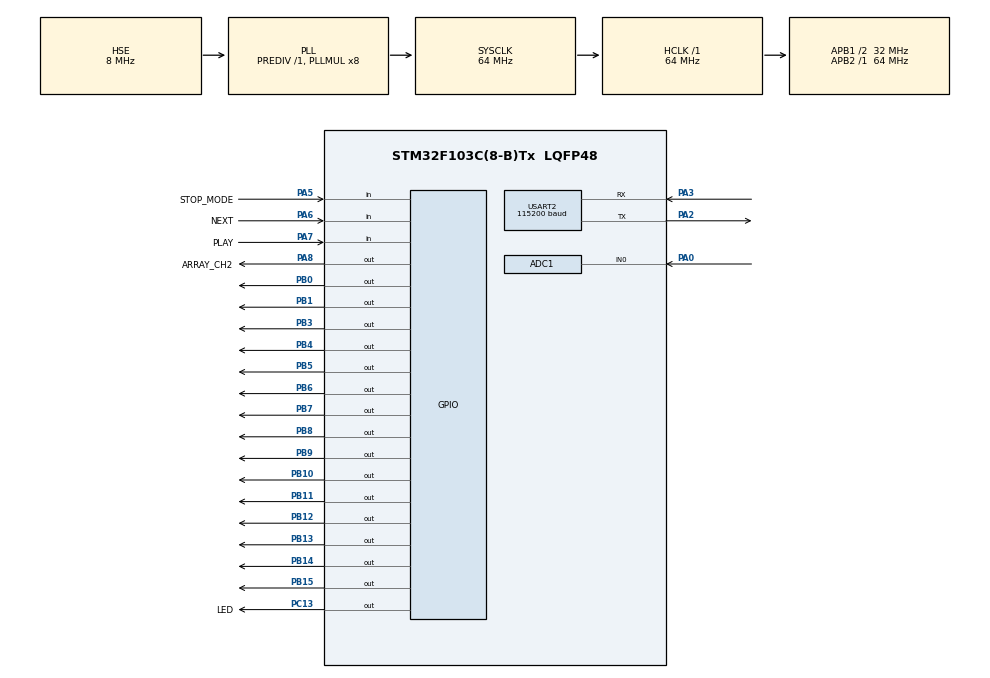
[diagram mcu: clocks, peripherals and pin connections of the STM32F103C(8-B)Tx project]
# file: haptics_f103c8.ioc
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ADC1.Channel-0\#ChannelRegularConversion=ADC_CHANNEL_0
ADC1.ExternalTrigConv=ADC_EXTERNALTRIGCONV_T3_TRGO
ADC1.NbrOfConversionFlag=1
ADC1.Rank-0\#ChannelRegularConversion=1
ADC1.SamplingTime-0\#ChannelRegularConversion=ADC_SAMPLETIME_7CYCLES_5
ADC1.master=1
Dma.ADC1.0.Direction=DMA_PERIPH_TO_MEMORY
Dma.ADC1.0.Instance=DMA1_Channel1
Dma.ADC1.0.MemDataAlignment=DMA_MDATAALIGN_HALFWORD
Dma.ADC1.0.MemInc=DMA_MINC_ENABLE
Dma.ADC1.0.Mode=DMA_NORMAL
Dma.ADC1.0.PeriphDataAlignment=DMA_PDATAALIGN_HALFWORD
Dma.ADC1.0.PeriphInc=DMA_PINC_DISABLE
Dma.ADC1.0.Priority=DMA_PRIORITY_LOW
Dma.Request0=ADC1
Dma.Request1=TIM1_UP
Dma.Request2=TIM1_CH1
Dma.TIM1_CH1.2.Direction=DMA_MEMORY_TO_PERIPH
Dma.TIM1_CH1.2.Instance=DMA1_Channel2
Dma.TIM1_CH1.2.MemDataAlignment=DMA_MDATAALIGN_HALFWORD
Dma.TIM1_CH1.2.MemInc=DMA_MINC_ENABLE
Dma.TIM1_CH1.2.Mode=DMA_CIRCULAR
Dma.TIM1_CH1.2.PeriphDataAlignment=DMA_PDATAALIGN_HALFWORD
Dma.TIM1_CH1.2.PeriphInc=DMA_PINC_DISABLE
Dma.TIM1_CH1.2.Priority=DMA_PRIORITY_VERY_HIGH
Dma.TIM1_UP.1.Direction=DMA_MEMORY_TO_PERIPH
Dma.TIM1_UP.1.Instance=DMA1_Channel5
Dma.TIM1_UP.1.MemDataAlignment=DMA_MDATAALIGN_HALFWORD
Dma.TIM1_UP.1.MemInc=DMA_MINC_ENABLE
Dma.TIM1_UP.1.Mode=DMA_CIRCULAR
Dma.TIM1_UP.1.PeriphDataAlignment=DMA_PDATAALIGN_HALFWORD
Dma.TIM1_UP.1.PeriphInc=DMA_PINC_DISABLE
Dma.TIM1_UP.1.Priority=DMA_PRIORITY_VERY_HIGH
Mcu.Family=STM32F1
Mcu.Name=STM32F103C(8-B)Tx
Mcu.Package=LQFP48
NVIC.DMA1_Channel1_IRQn=true\:2\:0\:false\:false\:true\:false\:true\:true
NVIC.DMA1_Channel2_IRQn=true\:1\:0\:false\:false\:true\:false\:true\:true
NVIC.DMA1_Channel5_IRQn=true\:1\:0\:false\:false\:true\:false\:true\:true
NVIC.PriorityGroup=NVIC_PRIORITYGROUP_4
NVIC.USART2_IRQn=true\:0\:0\:false\:false\:true\:false\:true\:true
PA0-WKUP.Signal=ADCx_IN0
PA13.Mode=Serial_Wire
PA13.Signal=SYS_JTMS-SWDIO
PA14.Mode=Serial_Wire
PA14.Signal=SYS_JTCK-SWCLK
PA2.Mode=Asynchronous
PA2.Signal=USART2_TX
PA3.GPIO_PuPd=GPIO_PULLUP
PA3.Mode=Asynchronous
PA3.Signal=USART2_RX
PA5.GPIO_Label=STOP_MODE
PA5.GPIO_PuPd=GPIO_PULLUP
PA5.Signal=GPIO_Input
PA6.GPIO_Label=NEXT
PA6.GPIO_PuPd=GPIO_PULLUP
PA6.Signal=GPIO_Input
PA7.GPIO_Label=PLAY
PA7.GPIO_PuPd=GPIO_PULLUP
PA7.Signal=GPIO_Input
PA8.GPIO_Label=ARRAY_CH2
PA8.GPIO_Speed=GPIO_SPEED_FREQ_HIGH
PA8.Signal=GPIO_Output
PB0.GPIO_Speed=GPIO_SPEED_FREQ_HIGH
PB0.Signal=GPIO_Output
PB1.GPIO_Speed=GPIO_SPEED_FREQ_HIGH
PB1.Signal=GPIO_Output
PB10.GPIO_Speed=GPIO_SPEED_FREQ_HIGH
PB10.Signal=GPIO_Output
PB11.GPIO_Speed=GPIO_SPEED_FREQ_HIGH
PB11.Signal=GPIO_Output
PB12.GPIO_Speed=GPIO_SPEED_FREQ_HIGH
PB12.Signal=GPIO_Output
PB13.GPIO_Speed=GPIO_SPEED_FREQ_HIGH
PB13.Signal=GPIO_Output
PB14.GPIO_Speed=GPIO_SPEED_FREQ_HIGH
PB14.Signal=GPIO_Output
PB15.GPIO_Speed=GPIO_SPEED_FREQ_HIGH
PB15.Signal=GPIO_Output
PB3.GPIO_Speed=GPIO_SPEED_FREQ_HIGH
PB3.Signal=GPIO_Output
PB4.GPIO_Speed=GPIO_SPEED_FREQ_HIGH
PB4.Signal=GPIO_Output
PB5.GPIO_Speed=GPIO_SPEED_FREQ_HIGH
PB5.Signal=GPIO_Output
PB6.GPIO_Speed=GPIO_SPEED_FREQ_HIGH
PB6.Signal=GPIO_Output
PB7.GPIO_Speed=GPIO_SPEED_FREQ_HIGH
PB7.Signal=GPIO_Output
PB8.GPIO_Speed=GPIO_SPEED_FREQ_HIGH
PB8.Signal=GPIO_Output
PB9.GPIO_Speed=GPIO_SPEED_FREQ_HIGH
PB9.Signal=GPIO_Output
PC13-TAMPER-RTC.GPIO_Label=LED
PC13-TAMPER-RTC.PinState=GPIO_PIN_SET
PC13-TAMPER-RTC.Signal=GPIO_Output
PD0-OSC_IN.Mode=HSE-External-Oscillator
PD0-OSC_IN.Signal=RCC_OSC_IN
PD1-OSC_OUT.Mode=HSE-External-Oscillator
PD1-OSC_OUT.Signal=RCC_OSC_OUT
ProjectManager.HeapSize=0x0
ProjectManager.StackSize=0x800
ProjectManager.TargetToolchain=STM32CubeIDE
RCC.ADCPresc=RCC_ADCPCLK2_DIV6
RCC.AHBFreq_Value=64000000
RCC.APB1CLKDivider=RCC_HCLK_DIV2
RCC.APB1Freq_Value=32000000
RCC.APB1TimFreq_Value=64000000
RCC.APB2Freq_Value=64000000
RCC.APB2TimFreq_Value=64000000
RCC.HCLKFreq_Value=64000000
RCC.HSE_VALUE=8000000
RCC.PLLMUL=RCC_PLL_MUL8
RCC.PLLSourceVirtual=RCC_PLLSOURCE_HSE
RCC.SYSCLKFreq_VALUE=64000000
RCC.SYSCLKSource=RCC_SYSCLKSOURCE_PLLCLK
RCC.USBFreq_Value=64000000
SH.ADCx_IN0.0=ADC1_IN0,IN0
TIM1.Channel-Output Compare1 No Output=TIM_CHANNEL_1
TIM1.Period=24
TIM1.Prescaler=0
TIM1.Pulse=1
TIM3.Period=159
TIM3.Prescaler=0
TIM3.TIM_MasterOutputTrigger=TIM_TRGO_UPDATE
USART2.BaudRate=115200
USART2.VirtualMode=VM_ASYNC
VP_TIM1_VS_ClockSourceINT.Mode=Internal
VP_TIM1_VS_no_output1.Mode=Output Compare1 No Output
VP_TIM3_VS_ClockSourceINT.Mode=Internal
board=custom

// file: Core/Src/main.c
/* USER CODE BEGIN Header */
/**
  ******************************************************************************
  * @file           : main.c
  * @brief          : Main program body
  ******************************************************************************
  * @attention
  *
  * Copyright (c) 2026 STMicroelectronics.
  * All rights reserved.
  *
  * This software is licensed under terms that can be found in the LICENSE file
  * in the root directory of this software component.
  * If no LICENSE file comes with this software, it is provided AS-IS.
  *
  ******************************************************************************
  */
/* USER CODE END Header */
#include "main.h"
#include "adc.h"
#include "dma.h"
#include "tim.h"
#include "usart.h"
#include "gpio.h"

/* USER CODE BEGIN Includes */
#include "app_f103.h"
/* USER CODE END Includes */

void SystemClock_Config(void);

int main(void)
{

  /* MCU Configuration--------------------------------------------------------*/

  /* Reset of all peripherals, Initializes the Flash interface and the Systick. */
  HAL_Init();

  /* Configure the system clock */
  SystemClock_Config();

  /* Initialize all configured peripherals */
  MX_GPIO_Init();
  MX_DMA_Init();
  MX_TIM1_Init();
  MX_TIM3_Init();
  MX_ADC1_Init();
  MX_USART2_UART_Init();
  /* USER CODE BEGIN 2 */
  app_f103_init();
  /* USER CODE END 2 */

  /* Infinite loop */
  while (1)
  {

    /* USER CODE BEGIN 3 */
    app_f103_poll();
  }
  /* USER CODE END 3 */
}

void SystemClock_Config(void)
{
  RCC_OscInitTypeDef RCC_OscInitStruct = {0};
  RCC_ClkInitTypeDef RCC_ClkInitStruct = {0};
  RCC_PeriphCLKInitTypeDef PeriphClkInit = {0};

  /** Initializes the RCC Oscillators according to the specified parameters
  * in the RCC_OscInitTypeDef structure.
  */
  RCC_OscInitStruct.OscillatorType = RCC_OSCILLATORTYPE_HSE;
  RCC_OscInitStruct.HSEState = RCC_HSE_ON;
  RCC_OscInitStruct.HSEPredivValue = RCC_HSE_PREDIV_DIV1;
  RCC_OscInitStruct.HSIState = RCC_HSI_ON;
  RCC_OscInitStruct.PLL.PLLState = RCC_PLL_ON;
  RCC_OscInitStruct.PLL.PLLSource = RCC_PLLSOURCE_HSE;
  RCC_OscInitStruct.PLL.PLLMUL = RCC_PLL_MUL8;
  if (HAL_RCC_OscConfig(&RCC_OscInitStruct) != HAL_OK)
  {
    Error_Handler();
  }

  /** Initializes the CPU, AHB and APB buses clocks
  */
  RCC_ClkInitStruct.ClockType = RCC_CLOCKTYPE_HCLK|RCC_CLOCKTYPE_SYSCLK
                              |RCC_CLOCKTYPE_PCLK1|RCC_CLOCKTYPE_PCLK2;
  RCC_ClkInitStruct.SYSCLKSource = RCC_SYSCLKSOURCE_PLLCLK;
  RCC_ClkInitStruct.AHBCLKDivider = RCC_SYSCLK_DIV1;
  RCC_ClkInitStruct.APB1CLKDivider = RCC_HCLK_DIV2;
  RCC_ClkInitStruct.APB2CLKDivider = RCC_HCLK_DIV1;

  if (HAL_RCC_ClockConfig(&RCC_ClkInitStruct, FLASH_LATENCY_2) != HAL_OK)
  {
    Error_Handler();
  }
  PeriphClkInit.PeriphClockSelection = RCC_PERIPHCLK_ADC;
  PeriphClkInit.AdcClockSelection = RCC_ADCPCLK2_DIV6;
  if (HAL_RCCEx_PeriphCLKConfig(&PeriphClkInit) != HAL_OK)
  {
    Error_Handler();
  }
}

void Error_Handler(void)
{
  /* USER CODE BEGIN Error_Handler_Debug */
  app_f103_shutdown();
  /* User can add his own implementation to report the HAL error return state */
  __disable_irq();
  while (1)
  {
  }
  /* USER CODE END Error_Handler_Debug */
}
